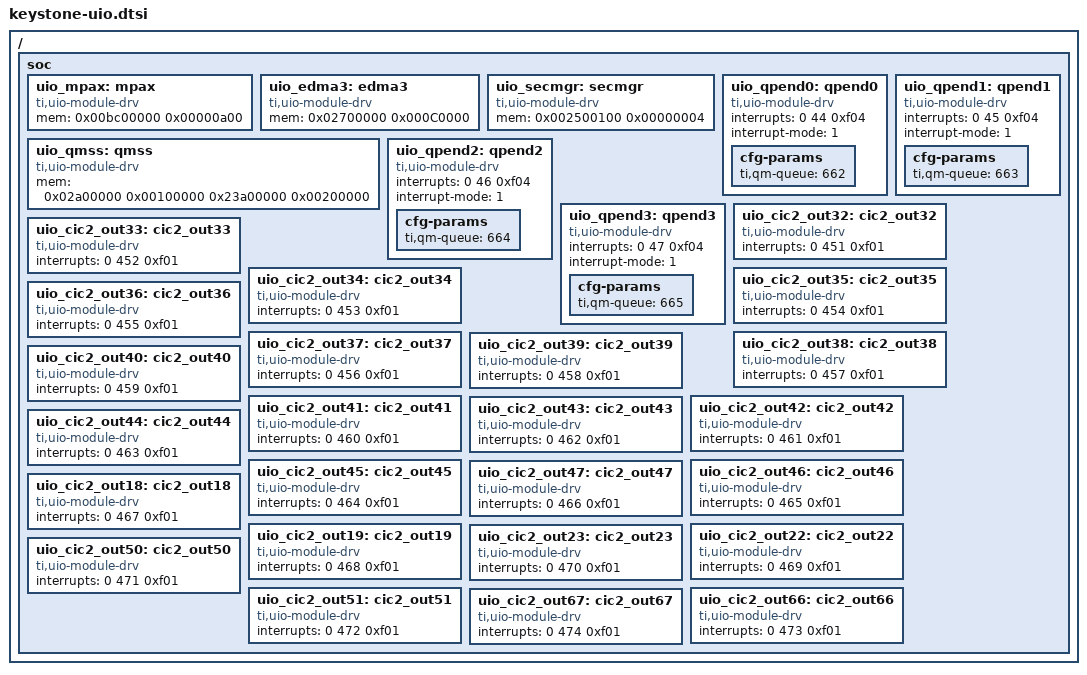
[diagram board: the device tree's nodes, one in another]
/ {
	soc {
		uio_mpax: mpax {
			compatible = "ti,uio-module-drv";
			mem  = <0x00bc00000 0x00000a00>;
		};

		uio_edma3: edma3 {
			compatible = "ti,uio-module-drv";
			mem = <0x02700000 0x000C0000>;
		};
		uio_secmgr: secmgr {
			compatible = "ti,uio-module-drv";
			mem  = <0x002500100 0x00000004>;
		};
		uio_qmss: qmss {
			compatible = "ti,uio-module-drv";
			mem  = <0x02a00000 0x00100000
				0x23a00000 0x00200000>;
		};

		uio_qpend0: qpend0 {
			compatible = "ti,uio-module-drv";
			interrupts = <0 44 0xf04>;
			interrupt-mode = <1>; /* Interrupt mode oneshot */
			cfg-params
			{
				ti,qm-queue = <662>;
			};
		};

		uio_qpend1: qpend1 {
			compatible = "ti,uio-module-drv";
			interrupts = <0 45 0xf04>;
			interrupt-mode = <1>; /* Interrupt mode oneshot */
			cfg-params
			{
				ti,qm-queue = <663>;
			};
		};

		uio_qpend2: qpend2 {
			compatible = "ti,uio-module-drv";
			interrupts = <0 46 0xf04>;
			interrupt-mode = <1>; /* Interrupt mode oneshot */
			cfg-params
			{
				ti,qm-queue = <664>;
			};
		};

		uio_qpend3: qpend3 {
			compatible = "ti,uio-module-drv";
			interrupts = <0 47 0xf04>;
			interrupt-mode = <1>; /* Interrupt mode oneshot */
			cfg-params
			{
				ti,qm-queue = <665>;
			};
		};

		/* The following uio cic2 entries allow access to interupt output
		 * by the cic2 controller: The actual input event triggering the
		 * interrupt is assumed to be programmed other drivers
		 */
		uio_cic2_out32: cic2_out32 {
			compatible = "ti,uio-module-drv";
			interrupts = <0 451 0xf01>;
		};

		uio_cic2_out33: cic2_out33 {
			compatible = "ti,uio-module-drv";
			interrupts = <0 452 0xf01>;
		};

		uio_cic2_out34: cic2_out34 {
			compatible = "ti,uio-module-drv";
			interrupts = <0 453 0xf01>;
		};

		uio_cic2_out35: cic2_out35 {
			compatible = "ti,uio-module-drv";
			interrupts = <0 454 0xf01>;
		};

		uio_cic2_out36: cic2_out36 {
			compatible = "ti,uio-module-drv";
			interrupts = <0 455 0xf01>;
		};

		uio_cic2_out37: cic2_out37 {
			compatible = "ti,uio-module-drv";
			interrupts = <0 456 0xf01>;
		};

		uio_cic2_out38: cic2_out38 {
			compatible = "ti,uio-module-drv";
			interrupts = <0 457 0xf01>;
		};

		uio_cic2_out39: cic2_out39 {
			compatible = "ti,uio-module-drv";
			interrupts = <0 458 0xf01>;
		};

		uio_cic2_out40: cic2_out40 {
			compatible = "ti,uio-module-drv";
			interrupts = <0 459 0xf01>;
		};

		uio_cic2_out41: cic2_out41 {
			compatible = "ti,uio-module-drv";
			interrupts = <0 460 0xf01>;
		};

		uio_cic2_out42: cic2_out42 {
			compatible = "ti,uio-module-drv";
			interrupts = <0 461 0xf01>;
		};

		uio_cic2_out43: cic2_out43 {
			compatible = "ti,uio-module-drv";
			interrupts = <0 462 0xf01>;
		};

		uio_cic2_out44: cic2_out44 {
			compatible = "ti,uio-module-drv";
			interrupts = <0 463 0xf01>;
		};

		uio_cic2_out45: cic2_out45 {
			compatible = "ti,uio-module-drv";
			interrupts = <0 464 0xf01>;
		};

		uio_cic2_out46: cic2_out46 {
			compatible = "ti,uio-module-drv";
			interrupts = <0 465 0xf01>;
		};

		uio_cic2_out47: cic2_out47 {
			compatible = "ti,uio-module-drv";
			interrupts = <0 466 0xf01>;
		};

		uio_cic2_out18: cic2_out18 {
			compatible = "ti,uio-module-drv";
			interrupts = <0 467 0xf01>;
		};

		uio_cic2_out19: cic2_out19 {
			compatible = "ti,uio-module-drv";
			interrupts = <0 468 0xf01>;
		};

		uio_cic2_out22: cic2_out22 {
			compatible = "ti,uio-module-drv";
			interrupts = <0 469 0xf01>;
		};

		uio_cic2_out23: cic2_out23 {
			compatible = "ti,uio-module-drv";
			interrupts = <0 470 0xf01>;
		};

		uio_cic2_out50: cic2_out50 {
			compatible = "ti,uio-module-drv";
			interrupts = <0 471 0xf01>;
		};

		uio_cic2_out51: cic2_out51 {
			compatible = "ti,uio-module-drv";
			interrupts = <0 472 0xf01>;
		};

		uio_cic2_out66: cic2_out66 {
			compatible = "ti,uio-module-drv";
			interrupts = <0 473 0xf01>;
		};

		uio_cic2_out67: cic2_out67 {
			compatible = "ti,uio-module-drv";
			interrupts = <0 474 0xf01>;
		};
	};
};
